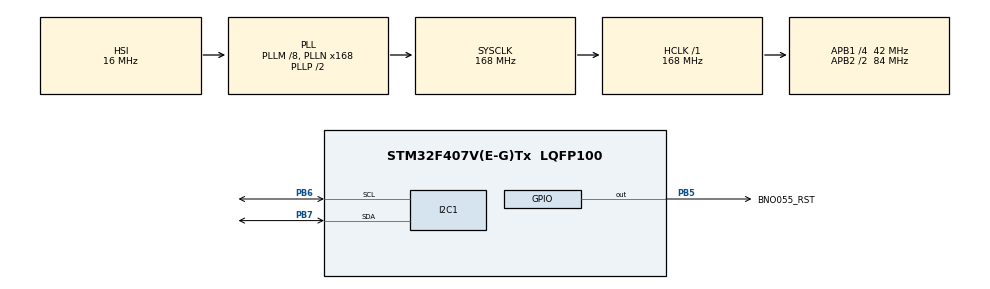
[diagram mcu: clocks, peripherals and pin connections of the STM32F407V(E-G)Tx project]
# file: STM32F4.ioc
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I2C1.I2C_Mode=I2C_Fast
Mcu.Family=STM32F4
Mcu.Name=STM32F407V(E-G)Tx
Mcu.Package=LQFP100
NVIC.PriorityGroup=NVIC_PRIORITYGROUP_4
PA13.Mode=Serial_Wire
PA13.Signal=SYS_JTMS-SWDIO
PA14.Mode=Serial_Wire
PA14.Signal=SYS_JTCK-SWCLK
PB5.GPIO_Label=BNO055_RST
PB5.PinState=GPIO_PIN_SET
PB5.Signal=GPIO_Output
PB6.Mode=I2C
PB6.Signal=I2C1_SCL
PB7.Mode=I2C
PB7.Signal=I2C1_SDA
PH0-OSC_IN.Mode=HSE-External-Oscillator
PH0-OSC_IN.Signal=RCC_OSC_IN
PH1-OSC_OUT.Mode=HSE-External-Oscillator
PH1-OSC_OUT.Signal=RCC_OSC_OUT
ProjectManager.HeapSize=0x200
ProjectManager.StackSize=0x400
ProjectManager.TargetToolchain=CMake
RCC.48MHZClocksFreq_Value=84000000
RCC.AHBFreq_Value=168000000
RCC.APB1CLKDivider=RCC_HCLK_DIV4
RCC.APB1Freq_Value=42000000
RCC.APB1TimFreq_Value=84000000
RCC.APB2CLKDivider=RCC_HCLK_DIV2
RCC.APB2Freq_Value=84000000
RCC.APB2TimFreq_Value=168000000
RCC.CortexFreq_Value=168000000
RCC.HCLKFreq_Value=168000000
RCC.HSE_VALUE=25000000
RCC.HSI_VALUE=16000000
RCC.LSE_VALUE=32768
RCC.PLLM=8
RCC.PLLN=168
RCC.SYSCLKFreq_VALUE=168000000
RCC.SYSCLKSource=RCC_SYSCLKSOURCE_PLLCLK
RCC.VCOOutputFreq_Value=336000000
board=custom

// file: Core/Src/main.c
/* USER CODE BEGIN Header */
/**
  ******************************************************************************
  * @file           : main.c
  * @brief          : Main program body
  ******************************************************************************
  * @attention
  *
  * Copyright (c) 2026 STMicroelectronics.
  * All rights reserved.
  *
  * This software is licensed under terms that can be found in the LICENSE file
  * in the root directory of this software component.
  * If no LICENSE file comes with this software, it is provided AS-IS.
  *
  ******************************************************************************
  */
/* USER CODE END Header */
#include "main.h"
#include "i2c.h"
#include "gpio.h"

/* USER CODE BEGIN Includes */
#include "bno055.h"
#include "bno055_calib_profile.h"
/* USER CODE END Includes */

/* USER CODE BEGIN PD */
#define BNO055_READ_PERIOD_MS  10U   /* fusion output data rate 100 Hz (Table 3-14) */
/* USER CODE END PD */

/* USER CODE BEGIN PV */
BNO055_HandleTypeDef hbno055;
BNO055_Status_t      bno055_init_status;
BNO055_Status_t      bno055_read_status;
BNO055_Euler_t       bno055_euler;
BNO055_CalibStatus_t bno055_calib;
static uint32_t      bno055_last_tick;
#if BNO055_CALIB_PROFILE_VALID
static const uint8_t bno055_calib_profile[BNO055_CALIB_PROFILE_SIZE] = BNO055_CALIB_PROFILE_DATA;
#endif
/* Captured once fully calibrated, read by Tools/bno055_dump_calib */
uint8_t              bno055_calib_captured[BNO055_CALIB_PROFILE_SIZE];
uint8_t              bno055_calib_captured_valid;
/* USER CODE END PV */

void SystemClock_Config(void);

int main(void)
{

  /* MCU Configuration--------------------------------------------------------*/

  /* Reset of all peripherals, Initializes the Flash interface and the Systick. */
  HAL_Init();

  /* Configure the system clock */
  SystemClock_Config();

  /* Initialize all configured peripherals */
  MX_GPIO_Init();
  MX_I2C1_Init();
  /* USER CODE BEGIN 2 */
  hbno055.hi2c            = &hi2c1;
  hbno055.address         = BNO055_I2C_ADDR_COM3_HIGH;   /* ADR floating -> 0x29 */
  hbno055.rst_port        = BNO055_RST_GPIO_Port;
  hbno055.rst_pin         = BNO055_RST_Pin;
  hbno055.mode            = BNO055_OPR_MODE_NDOF;
  hbno055.use_ext_crystal = true;                        /* 32.768 kHz on GY-BNO055 */
#if BNO055_CALIB_PROFILE_VALID
  hbno055.calib_profile   = bno055_calib_profile;        /* from git, bno055_calib_profile.h */
#else
  hbno055.calib_profile   = NULL;
#endif
  bno055_init_status = BNO055_Init(&hbno055);
  /* USER CODE END 2 */

  /* Infinite loop */
  while (1)
  {

    /* USER CODE BEGIN 3 */
    if ((bno055_init_status == BNO055_OK) &&
        ((HAL_GetTick() - bno055_last_tick) >= BNO055_READ_PERIOD_MS))
    {
      bno055_last_tick = HAL_GetTick();
      bno055_read_status = BNO055_ReadEuler(&hbno055, &bno055_euler);
      (void)BNO055_ReadCalibStatus(&hbno055, &bno055_calib);

      if ((bno055_calib_captured_valid == 0U) &&
          (bno055_calib.sys == 3U) && (bno055_calib.gyr == 3U) &&
          (bno055_calib.acc == 3U) && (bno055_calib.mag == 3U))
      {
        if (BNO055_ReadCalibProfile(&hbno055, bno055_calib_captured) == BNO055_OK)
        {
          bno055_calib_captured_valid = 1U;
        }
      }
    }
  }
  /* USER CODE END 3 */
}

void SystemClock_Config(void)
{
  RCC_OscInitTypeDef RCC_OscInitStruct = {0};
  RCC_ClkInitTypeDef RCC_ClkInitStruct = {0};

  /** Configure the main internal regulator output voltage
  */
  __HAL_RCC_PWR_CLK_ENABLE();
  __HAL_PWR_VOLTAGESCALING_CONFIG(PWR_REGULATOR_VOLTAGE_SCALE1);

  /** Initializes the RCC Oscillators according to the specified parameters
  * in the RCC_OscInitTypeDef structure.
  */
  RCC_OscInitStruct.OscillatorType = RCC_OSCILLATORTYPE_HSI;
  RCC_OscInitStruct.HSIState = RCC_HSI_ON;
  RCC_OscInitStruct.HSICalibrationValue = RCC_HSICALIBRATION_DEFAULT;
  RCC_OscInitStruct.PLL.PLLState = RCC_PLL_ON;
  RCC_OscInitStruct.PLL.PLLSource = RCC_PLLSOURCE_HSI;
  RCC_OscInitStruct.PLL.PLLM = 8;
  RCC_OscInitStruct.PLL.PLLN = 168;
  RCC_OscInitStruct.PLL.PLLP = RCC_PLLP_DIV2;
  RCC_OscInitStruct.PLL.PLLQ = 4;
  if (HAL_RCC_OscConfig(&RCC_OscInitStruct) != HAL_OK)
  {
    Error_Handler();
  }

  /** Initializes the CPU, AHB and APB buses clocks
  */
  RCC_ClkInitStruct.ClockType = RCC_CLOCKTYPE_HCLK|RCC_CLOCKTYPE_SYSCLK
                              |RCC_CLOCKTYPE_PCLK1|RCC_CLOCKTYPE_PCLK2;
  RCC_ClkInitStruct.SYSCLKSource = RCC_SYSCLKSOURCE_PLLCLK;
  RCC_ClkInitStruct.AHBCLKDivider = RCC_SYSCLK_DIV1;
  RCC_ClkInitStruct.APB1CLKDivider = RCC_HCLK_DIV4;
  RCC_ClkInitStruct.APB2CLKDivider = RCC_HCLK_DIV2;

  if (HAL_RCC_ClockConfig(&RCC_ClkInitStruct, FLASH_LATENCY_5) != HAL_OK)
  {
    Error_Handler();
  }
}

void Error_Handler(void)
{
  __disable_irq();
  while (1)
  {
  }
}
